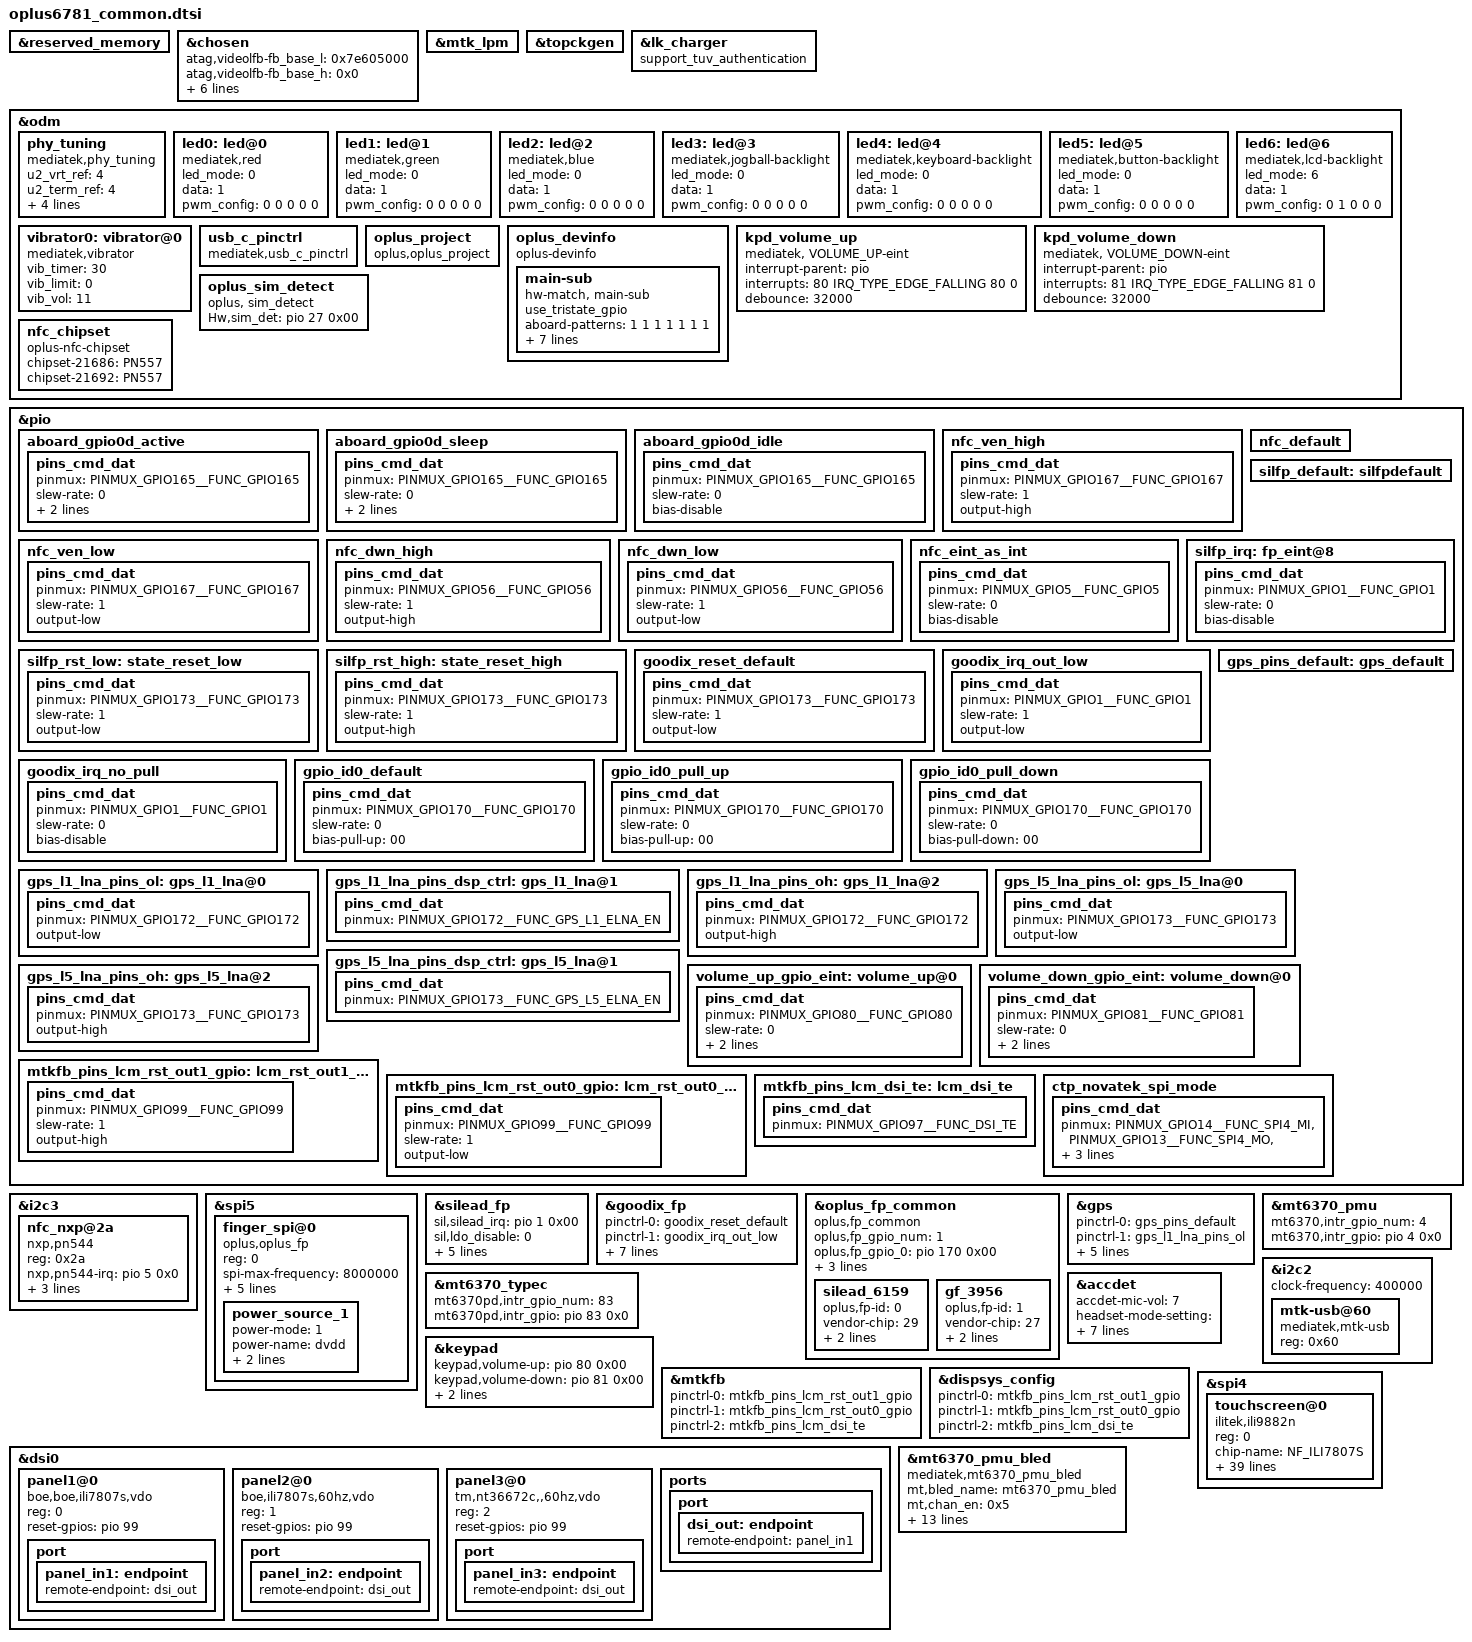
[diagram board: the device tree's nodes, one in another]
/*
 * Copyright (C) 2015 MediaTek Inc.
 *
 * This program is free software: you can redistribute it and/or modify
 * it under the terms of the GNU General Public License version 2 as
 * published by the Free Software Foundation.
 *
 * This program is distributed in the hope that it will be useful,
 * but WITHOUT ANY WARRANTY; without even the implied warranty of
 * MERCHANTABILITY or FITNESS FOR A PARTICULAR PURPOSE. See the
 * GNU General Public License for more details.
 */
#include <dt-bindings/interrupt-controller/irq.h>
#include <dt-bindings/interrupt-controller/arm-gic.h>
#include <dt-bindings/pinctrl/mt6781-pinfunc.h>

&reserved_memory {
};

/* chosen */
&chosen {
	/* fpga may has no lk, we need to specify display info here */
	/* fb buffer is reserved using this dts by memory node above */
	atag,videolfb-fb_base_l = <0x7e605000>;
	atag,videolfb-fb_base_h = <0x0>;
	atag,videolfb-islcmfound = <1>;
	atag,videolfb-islcm_inited = <0>;
	atag,videolfb-fps= <6000>;
	atag,videolfb-vramSize= <0x017e8000>;
	atag,videolfb-lcmname=
		"nt35695_fhd_dsi_cmd_truly_rt5081_drv";
};

&mtk_lpm {
};

&topckgen {
};

&lk_charger {
	support_tuv_authentication;
};

&odm {
	phy_tuning {
		compatible = "mediatek,phy_tuning";
		u2_vrt_ref = <4>;
		u2_term_ref = <4>;
		u2_enhance = <3>;

		host_u2_vrt_ref = <2>;
		host_u2_term_ref = <2>;
		host_u2_enhance = <2>;
	};
};

&odm {
	led0:led@0 {
		compatible = "mediatek,red";
		led_mode = <0>;
		data = <1>;
		pwm_config = <0 0 0 0 0>;
	};
	led1:led@1 {
		compatible = "mediatek,green";
		led_mode = <0>;
		data = <1>;
		pwm_config = <0 0 0 0 0>;
	};
	led2:led@2 {
		compatible = "mediatek,blue";
		led_mode = <0>;
		data = <1>;
		pwm_config = <0 0 0 0 0>;
	};
	led3:led@3 {
		compatible = "mediatek,jogball-backlight";
		led_mode = <0>;
		data = <1>;
		pwm_config = <0 0 0 0 0>;
	};
	led4:led@4 {
		compatible = "mediatek,keyboard-backlight";
		led_mode = <0>;
		data = <1>;
		pwm_config = <0 0 0 0 0>;
	};
	led5:led@5 {
		compatible = "mediatek,button-backlight";
		led_mode = <0>;
		data = <1>;
		pwm_config = <0 0 0 0 0>;
	};
	led6:led@6 {
		compatible = "mediatek,lcd-backlight";
/* #ifdef OPLUS_BUG_COMPATIBILITY */
		led_mode = <6>;
/* #endif */
		data = <1>;
		pwm_config = <0 1 0 0 0>;
	};
	vibrator0:vibrator@0 {
		compatible = "mediatek,vibrator";
		/*vib_timer = <25>;
		vib_limit = <9>;
		vib_vol= <9>;*/
		vib_timer = <30>;
		vib_limit = <0>;
		vib_vol= <11>;
	};

	usb_c_pinctrl:usb_c_pinctrl {
		compatible = "mediatek,usb_c_pinctrl";
	};

	oplus_project:oplus_project {
		compatible = "oplus,oplus_project";
	};
	oplus_devinfo:oplus_devinfo {
		compatible = "oplus-devinfo";

		main-sub {
			compatible = "hw-match, main-sub";
			use_tristate_gpio;
			aboard-patterns = <1 1 1 1 1 1 1>;
			aboard-patterns-evt2 = <1 1 1 1 1 2 2>;
			/*main board*/
			match-projects = <21684 21685 21686 21687 21690 21691 21692>;
			aboard-gpio0 = <&pio 165 0x0>;
			pinctrl-names = "aboard_gpio0d_active", "aboard_gpio0d_sleep", "aboard_gpio0d_idle";
			pinctrl-0 = <&aboard_gpio0d_active>;
			pinctrl-1 = <&aboard_gpio0d_sleep>;
			pinctrl-2 = <&aboard_gpio0d_idle>;
		};
	};

	kpd_volume_up:kpd_volume_up {
               compatible = "mediatek, VOLUME_UP-eint";
               interrupt-parent = <&pio>;
               interrupts = <80 IRQ_TYPE_EDGE_FALLING 80 0>;
               debounce = <32000>;
               status = "okay";
       };

	kpd_volume_down:kpd_volume_down {
			compatible = "mediatek, VOLUME_DOWN-eint";
			interrupt-parent = <&pio>;
			interrupts = <81 IRQ_TYPE_EDGE_FALLING 81 0>;
			debounce = <32000>;
			status = "okay";
	};

	//#ifdef OPLUS_FEATURE_TP_BASIC
		oplus_sim_detect {
			compatible = "oplus, sim_detect";
			Hw,sim_det = <&pio 27 0x00>;
		};
	//#endif /* OPLUS_FEATURE_TP_BASIC */

//#ifdef OPLUS_FEATURE_NFC_BRINGUP
    nfc_chipset:nfc_chipset {
        compatible = "oplus-nfc-chipset";
        chipset-21686 = "PN557";
        chipset-21692 = "PN557";
    };
//#endif /* OPLUS_FEATURE_NFC_BRINGUP */
};

&pio {
	aboard_gpio0d_active: aboard_gpio0d_active {
		pins_cmd_dat {
			pinmux = <PINMUX_GPIO165__FUNC_GPIO165>;
			slew-rate = <0>;
			bias-pull-up = <01>;
			input-enable;
		};
	};
	aboard_gpio0d_sleep: aboard_gpio0d_sleep {
		pins_cmd_dat {
			pinmux = <PINMUX_GPIO165__FUNC_GPIO165>;
			slew-rate = <0>;
			bias-pull-up = <00>;
			input-enable;
		};
	};
	aboard_gpio0d_idle: aboard_gpio0d_idle {
		pins_cmd_dat {
			pinmux = <PINMUX_GPIO165__FUNC_GPIO165>;
			slew-rate = <0>;
			bias-disable;
		};
	};
};

//#ifdef OPLUS_FEATURE_NFC_BRINGUP
/* NFC GPIO standardization start */
&pio {
    nfc_ven_high: nfc_ven_high {
                pins_cmd_dat {
                        pinmux = <PINMUX_GPIO167__FUNC_GPIO167>;
                        slew-rate = <1>;
                        output-high;
                };
        };
        nfc_ven_low: nfc_ven_low {
                pins_cmd_dat {
                        pinmux = <PINMUX_GPIO167__FUNC_GPIO167>;
                        slew-rate = <1>;
                        output-low;
                };
        };
        nfc_dwn_high: nfc_dwn_high {
                pins_cmd_dat {
                        pinmux = <PINMUX_GPIO56__FUNC_GPIO56>;
                        slew-rate = <1>;
                        output-high;
                };
        };
        nfc_dwn_low: nfc_dwn_low {
                pins_cmd_dat {
                        pinmux = <PINMUX_GPIO56__FUNC_GPIO56>;
                        slew-rate = <1>;
                        output-low;
                };
       };
        nfc_eint_as_int: nfc_eint_as_int {
          pins_cmd_dat {
                        pinmux = <PINMUX_GPIO5__FUNC_GPIO5>;
                        slew-rate = <0>;
                       bias-disable;
                };
        };
        nfc_default: nfc_default {
        };
};

&i2c3 {
       status = "okay";
       nfc_nxp@2a {
               compatible = "nxp,pn544";
               reg = <0x2a>;
               nxp,pn544-irq = <&pio 5 0x0>;
               nxp,pn544-ven = <&pio 167 0x0>;
               nxp,pn544-fw-dwnld = <&pio 56 0x0>;
               interrupt-parent = <&pio>;
       };
};
/* NFC GPIO standardization end */
//#endif /* OPLUS_FEATURE_NFC_BRINGUP */

&spi5 {
	#address-cells = <1>;
	#size-cells = <0>;
	status = "okay";
	finger_spi@0 {
	    compatible = "oplus,oplus_fp";
	    reg = <0>;
	    spi-max-frequency = <8000000>;
	    netlink-event = <30>;
	    spi-id = <1>;
	    spi-irq = <1>;
	    spi-reg = <0x11015000>;
	    dvdd-config = <3000000 3000000 150000>;
        status = "okay";
        power_source_1{
            power-mode = <1>;
            power-name = "dvdd";
            power-config = "dvdd-config";
            delay-time = <0>;
};
    };
};
/*-------------------the silead device config start----------------------*/
&pio {
	silfp_default: silfpdefault {
	};
	silfp_rst_low: state_reset_low {
		pins_cmd_dat {
			pinmux = <PINMUX_GPIO173__FUNC_GPIO173>;
			slew-rate = <1>;
			output-low;
		};
	};
	silfp_rst_high: state_reset_high {
		pins_cmd_dat {
			pinmux = <PINMUX_GPIO173__FUNC_GPIO173>;
			slew-rate = <1>;
			output-high;
		};
	};
	silfp_irq: fp_eint@8 {
		pins_cmd_dat {
			pinmux = <PINMUX_GPIO1__FUNC_GPIO1>;
			slew-rate = <0>;
			bias-disable;
		};
	};
};
&silead_fp {
	sil,silead_irq = <&pio 1 0x00>;
	sil,ldo_disable = <0>;
	vmch_enable = <2>;
	pinctrl-names = "default", "rst-low", "rst-high",
	                "irq-init";
	pinctrl-0 = <&silfp_default>;
	pinctrl-1 = <&silfp_rst_low>;
	pinctrl-2 = <&silfp_rst_high>;
	pinctrl-3 = <&silfp_irq>;
	status = "okay";
};
/*-------------------the silead device config end----------------------*/

&pio {
	goodix_reset_default: goodix_reset_default {
		pins_cmd_dat {
			pinmux = <PINMUX_GPIO173__FUNC_GPIO173>;
			slew-rate = <1>;
			output-low;
		};
	};
	goodix_irq_out_low: goodix_irq_out_low {
		pins_cmd_dat {
			pinmux = <PINMUX_GPIO1__FUNC_GPIO1>;
			slew-rate = <1>;
			output-low;
		};
	};
	goodix_irq_no_pull: goodix_irq_no_pull {
		pins_cmd_dat {
			pinmux = <PINMUX_GPIO1__FUNC_GPIO1>;
			slew-rate = <0>;
			bias-disable;
		};
	};
};

&goodix_fp {
	pinctrl-names = "goodix_reset_default", "goodix_irq_out_low", "goodix_irq_no_pull";
	pinctrl-0 = <&goodix_reset_default>;
	pinctrl-1 = <&goodix_irq_out_low>;
	pinctrl-2 = <&goodix_irq_no_pull>;
	interrupt-parent = <&pio>;
	interrupts = <1 0>;
	goodix,gpio_irq = <&pio 1 0x00>;
	goodix,gpio_reset = <&pio 173 0x00>;
	gf,cs_gpio_disable = <1>;
	spi-max-frequency = <8000000>;
	status = "okay";
};

/*the finger_id config to project dts.*/

&pio{
	gpio_id0_default: gpio_id0_default {
		pins_cmd_dat {
			pinmux = <PINMUX_GPIO170__FUNC_GPIO170>;
			slew-rate = <0>;
			bias-pull-up = <00>;
		};
	};
	gpio_id0_pull_up: gpio_id0_pull_up {
		pins_cmd_dat {
			pinmux = <PINMUX_GPIO170__FUNC_GPIO170>;
			slew-rate = <0>;
			bias-pull-up = <00>;
		};
	};
	gpio_id0_pull_down: gpio_id0_pull_down {
		pins_cmd_dat {
			pinmux = <PINMUX_GPIO170__FUNC_GPIO170>;
			slew-rate = <0>;
			bias-pull-down = <00>;
		};
	};
};

&oplus_fp_common {
	compatible = "oplus,fp_common"; //Manufacture, and Model
	oplus,fp_gpio_num = <1>;
	oplus,fp_gpio_0 = <&pio 170 0x00>;
	pinctrl-names = "gpio_id0_default", "gpio_id0_pull_up", "gpio_id0_pull_down";
	pinctrl-0 = <&gpio_id0_default>;
	pinctrl-1 = <&gpio_id0_pull_up>;
	pinctrl-2 = <&gpio_id0_pull_down>;

    silead_6159 {
            oplus,fp-id = <0>; /* fp id mapping table */
            vendor-chip = <29>; /* please refer to the struct fp_vendor_t in oplus_fp_commmon.n */
            eng-menu = "-1,-1"; /* represents SNR, inclination test item in engineer menu, and 0/1 means off/on */
            chip-name = "S_gsl6159";  /* /proc/fp_id, will be displayed in engineer menu  */
    };
    gf_3956 {
            oplus,fp-id = <1>; /* fp id mapping table */
            vendor-chip = <27>; /* please refer to the struct fp_vendor_t in oplus_fp_commmon.n */
            eng-menu = "-1,-1"; /* represents SNR, inclination test item in engineer menu, and 0/1 means off/on */
            chip-name = "G_3956";  /* /proc/fp_id, will be displayed in engineer menu  */
    };
};

/* GPS GPIO standardization start */
&pio {
	gps_pins_default: gps_default {
	};

	gps_l1_lna_pins_ol: gps_l1_lna@0 {
		pins_cmd_dat {
			pinmux = <PINMUX_GPIO172__FUNC_GPIO172>;
			output-low;
		};
	};
	gps_l1_lna_pins_dsp_ctrl: gps_l1_lna@1 {
		pins_cmd_dat {
			pinmux = <PINMUX_GPIO172__FUNC_GPS_L1_ELNA_EN>;
		};
	};
	gps_l1_lna_pins_oh: gps_l1_lna@2 {
		pins_cmd_dat {
			pinmux = <PINMUX_GPIO172__FUNC_GPIO172>;
			output-high;
		};
	};

	gps_l5_lna_pins_ol: gps_l5_lna@0 {
		pins_cmd_dat {
			pinmux = <PINMUX_GPIO173__FUNC_GPIO173>;
			output-low;
		};
	};
	gps_l5_lna_pins_dsp_ctrl: gps_l5_lna@1 {
		pins_cmd_dat {
			pinmux = <PINMUX_GPIO173__FUNC_GPS_L5_ELNA_EN>;
		};
	};
	gps_l5_lna_pins_oh: gps_l5_lna@2 {
		pins_cmd_dat {
			pinmux = <PINMUX_GPIO173__FUNC_GPIO173>;
			output-high;
		};
	};
};

&gps {
	pinctrl-names = "default",
		"gps_l1_lna_disable",
		"gps_l1_lna_dsp_ctrl",
		"gps_l1_lna_enable",
		"gps_l5_lna_disable",
		"gps_l5_lna_dsp_ctrl",
		"gps_l5_lna_enable";
	pinctrl-0 = <&gps_pins_default>;
	pinctrl-1 = <&gps_l1_lna_pins_ol>;
	pinctrl-2 = <&gps_l1_lna_pins_dsp_ctrl>;
	pinctrl-3 = <&gps_l1_lna_pins_oh>;
	pinctrl-4 = <&gps_l5_lna_pins_ol>;
	pinctrl-5 = <&gps_l5_lna_pins_dsp_ctrl>;
	pinctrl-6 = <&gps_l5_lna_pins_oh>;
	status = "okay";
};
/* GPS GPIO standardization end */

&mt6370_pmu {
	mt6370,intr_gpio_num = <4>; /* direct defined GPIO num */
	mt6370,intr_gpio = <&pio 4 0x0>;
};

&mt6370_typec {
	mt6370pd,intr_gpio_num = <83>; /* direct defined GPIO num */
	mt6370pd,intr_gpio = <&pio 83 0x0>;
};

&i2c2 {
	clock-frequency = <400000>;
	mtk-usb@60 {
		compatible = "mediatek,mtk-usb";
		reg = <0x60>;
		status = "okay";
	};
};

&keypad {
	keypad,volume-up	= <&pio 80 0x00>;
	keypad,volume-down	= <&pio 81 0x00>;
	pinctrl-names = "volume_up_as_int", "volume_down_as_int";
	pinctrl-0 = <&volume_up_gpio_eint>;
	pinctrl-1 = <&volume_down_gpio_eint>;
	status = "okay";
};

&pio {
	volume_up_gpio_eint:volume_up@0{
		pins_cmd_dat {
			pinmux = <PINMUX_GPIO80__FUNC_GPIO80>;
			slew-rate = <0>;  /*direction 0:in, 1:out*/
			bias-pull-up = <00>;
			input-enable;
		};
	};
	volume_down_gpio_eint:volume_down@0{
		pins_cmd_dat {
			pinmux = <PINMUX_GPIO81__FUNC_GPIO81>;
			slew-rate = <0>;  /*direction 0:in, 1:out*/
			bias-pull-up = <01>;
			input-enable;
		};
	};
};

/* accdet start */
&accdet {
	/* accdet micbias voltage: 0x07,2.7v;0x05,2.5v;0x02,1.9v */
	accdet-mic-vol = <7>;
	headset-mode-setting = <0x500 0x500 1 0x1f0 0x800 0x800 0x20 0x44>;
	accdet-plugout-debounce = <1>;
	/*1:ACC mode, 2:low cost without in bias, 6:low cost with in bias*/
	accdet-mic-mode = <1>;
	/* eint_level_trigger: 8,LEVEL_LOW(DEF) ;4,LV_HIGH;others,LV_LOW */
	headset-eint-level-pol = <8>;
	/*0--MD_MAX--UP_MAX--DW_MAX*/
	headset-three-key-threshold = <0 80 220 400>;
	headset-three-key-threshold-CDD = <0 121 192 600>;
	/*0--MD_MAX--VOICE_MAX--UP_MAX--DW_MAX*/
	headset-four-key-threshold = <0 58 121 192 400>;
	status = "okay";
};
/* accdet end */

#ifndef CONFIG_FPGA_EARLY_PORTING
&pio {
	mtkfb_pins_lcm_rst_out1_gpio: lcm_rst_out1_gpio {
		pins_cmd_dat {
			pinmux = <PINMUX_GPIO99__FUNC_GPIO99>;
			slew-rate = <1>;
			output-high;
		};
	};

	mtkfb_pins_lcm_rst_out0_gpio: lcm_rst_out0_gpio {
		pins_cmd_dat {
			pinmux = <PINMUX_GPIO99__FUNC_GPIO99>;
			slew-rate = <1>;
			output-low;
		};
	};
	mtkfb_pins_lcm_dsi_te: lcm_dsi_te {
		pins_cmd_dat {
			pinmux = <PINMUX_GPIO97__FUNC_DSI_TE>;
		};
	};
};

&mtkfb {
	pinctrl-names = "lcm_rst_out1_gpio", "lcm_rst_out0_gpio",
		"mode_te_te";
	pinctrl-0 = <&mtkfb_pins_lcm_rst_out1_gpio>;
	pinctrl-1 = <&mtkfb_pins_lcm_rst_out0_gpio>;
	pinctrl-2 = <&mtkfb_pins_lcm_dsi_te>;
	status = "okay";
};

&dispsys_config {
	pinctrl-names =
		"lcm_rst_out1_gpio", "lcm_rst_out0_gpio",
		"mode_te_te";
	pinctrl-0 = <&mtkfb_pins_lcm_rst_out1_gpio>;
	pinctrl-1 = <&mtkfb_pins_lcm_rst_out0_gpio>;
	pinctrl-2 = <&mtkfb_pins_lcm_dsi_te>;
	status = "okay";
};

&dsi0 {
	status = "okay";
	#address-cells = <1>;
	#size-cells = <0>;
	panel1@0 {
		compatible = "boe,boe,ili7807s,vdo";
		reg = <0>;
		reset-gpios = <&pio 99 0>;
		pinctrl-names = "default";
		port {
			panel_in1: endpoint {
				remote-endpoint = <&dsi_out>;
			};
		};
	};
    panel2@0 {
		compatible = "boe,ili7807s,60hz,vdo";
		reg = <1>;
		reset-gpios = <&pio 99 0>;
		pinctrl-names = "default";
		port {
			panel_in2: endpoint {
				remote-endpoint = <&dsi_out>;
			};
		};
	};
    panel3@0 {
		compatible = "tm,nt36672c,,60hz,vdo";
		reg = <2>;
		reset-gpios = <&pio 99 0>;
		pinctrl-names = "default";
		port {
			panel_in3: endpoint {
				remote-endpoint = <&dsi_out>;
			};
		};
	};
	ports {
		port {
			dsi_out: endpoint {
				remote-endpoint = <&panel_in1>;
			};
		};
	};
};

#endif

/* TOUCH start */
&spi4 {
	status = "okay";

	 touchscreen@0 {
		compatible = "ilitek,ili9882n";
		reg = <0>; //Same as CS ID
		chip-name = "NF_ILI7807S";
		status = "okay";

		spi-max-frequency = <9600000>;
		interrupt-parent = <&pio>;
		interrupts = <12 IRQ_TYPE_EDGE_FALLING 12 0>;
		irq-gpio = <&pio 12 0x2002>;
		reset-gpio = <&pio 121 0>;

		platform_support_project = <21684 21685 21686 21687 21690 21691 21692>;
		platform_support_project_dir = <21684 21685 21686 21687 21690 21691 21692>;
		platform_support_project_commandline = "default_commandline","default_commandline","default_commandline","default_commandline","default_commandline","default_commandline","default_commandline";

		touchpanel,max-num-support = <10>;
		touchpanel,tx-rx-num = <18 36>;
		touchpanel,panel-coords = <1080 2412>;
		touchpanel,display-coords = <1080 2412>;
		touchpanel,touchmajor-limit = <0 54>;
		pinctrl-names = "default","pin_set_low", "pin_set_high";
		pinctrl-0 = <&ctp_novatek_spi_mode>;

		prevention,dead_area_width = <20 20>;
		prevention,condition_area_width = <60 60 160 160>;
		prevention,eli_area_width = <240 1000 1200 240>;

		incell_screen;
		irq_need_dev_resume_ok;
		fw_edge_limit_support;
		black_gesture_support;
		charger_pump_support;
		headset_pump_support;
		esd_handle_support;
		black_gesture_test_support;
		game_switch_support;
		noflash_support;
		lcd_trigger_load_tp_fw_support;
		smart_gesture_support;
		pressure_report_support;
		fw_update_app_support;
		health_monitor_v2_support;
		touchpanel,button-type = <4>;
	};
};

&pio {
	ctp_novatek_spi_mode:ctp_novatek_spi_mode{
		pins_cmd_dat {
			pinmux = <PINMUX_GPIO14__FUNC_SPI4_MI>,
				<PINMUX_GPIO13__FUNC_SPI4_MO>,
				<PINMUX_GPIO144__FUNC_SPI4_CLK>,
				<PINMUX_GPIO145__FUNC_SPI4_CSB>;
			drive-strength = <4>;
		};
	};
};

&mt6370_pmu_bled {
	compatible = "mediatek,mt6370_pmu_bled";
	interrupt-names = "bled_ocp";
	mt,bled_name = "mt6370_pmu_bled";
	/* mt,ext_en_pin; */
	/* #ifdef OPLUS_BUG_COMPATIBILITY */
	mt,chan_en  = <0x5>; /* bit 0 1 2 3 -> chan 1 2 3 4 */
	/* #endif */
	mt,map_linear;
	mt,bl_ovp_level = <3>;	/* 0: 17v */
	/* 1: 21v */
	/* 2: 25v */
	/* 3: 29v */
	/* #ifdef OPLUS_BUG_COMPATIBILITY */
	mt,bl_ocp_level = <3>;	/* 0: 900mA */
	/* #endif */
	mt,pwm_fsample = <2>;	/* 0: 1MHz */
	/* 1: 4MHz */
	/* 2: or 3: 24mHz */
	mt,pwm_deglitch = <1>;	/* 0: no filter */
	/* 1: 100ns */
	/* 2: 160ns */
	/* 3: 200ns */
	mt,pwm_hys_en = <1>;	/* PWM Input Hysteresis */
	/* #ifdef OPLUS_BUG_COMPATIBILITY */
	mt,pwm_hys = <0>;	/* 0: 1 bit, 1: 2 bit */
	/* #endif */
	/* 2: 4 bit, 3: 6 bit */
	mt,pwm_avg_cycle = <0>; /* 0 disable avg, 1 avg 2 cycle, 2 avg 4 cycle */
	/* 3 avg 8 cycle, 4 avg 16 cycle, 5 avg 32 cycle */
	mt,bled_ramptime = <9>; /* 0, 500us, 750us, 1ms, 2ms, 5ms, 10ms, 20ms */
	/* 50ms, 100ms, 250ms, 800ms, 1s, 2s, 4s, 8s */
	mt,bled_flash_ramp = <1>; /* 0, 500us, 750us, 1ms, 2ms, 5ms */
	/* #ifdef OPLUS_BUG_COMPATIBILITY */
	mt,max_bled_brightness = <1878>; /* we have 11 bit resolution, quantize in driver */
	/* #endif */
	/* maximum 2047 */
	mt,bled_curr_scale = <0>;	/* 0: 30mA, 1: 22.5mA */
	/* 2: 20mA, 3: 17.5mA */
	/* If use bled lpf,
	 * Set	//mt,map_linear;
	 *	pwm_lpf_coef = <2>;
	 *	mt,pwm_lpf_en;
	 *	mt,bled_curr_mode;
	 * Else
	 * Set	mt,map_linear;
	 *	pwm_lpf_coef = <0>;
	 *	//mt,pwm_lpf_en;
	 *	//mt,bled_curr_mode;
	 */
	mt,pwm_lpf_coef = <0>;	/* 0: (1)/(2^15) */
	/* 1: (2)/(2^15) */
	/* 2: (3)/(2^15) */
	/* 3: (4)/(2^15) */
	/* with it, Alpha-LPF enable */
	/* mt,pwm_lpf_en; */
	/* with it, pwm duty is multiplied after
	 * linear/expenential mapper
	 */
	/* mt,bled_curr_mode; */
};

/*#include <oplus6781_20684/cust.dtsi>*/
/*#include "mediatek/cust_mt6781_camera.dtsi"*/
#include "camera_ldo_mt6781.dtsi"
#include "mediatek/cust_mt6781_camera_space.dtsi"
#include "mediatek/novatek-nt36xxx-space-spi.dtsi"
/*End of this file, DO NOT ADD ANYTHING HERE*/
